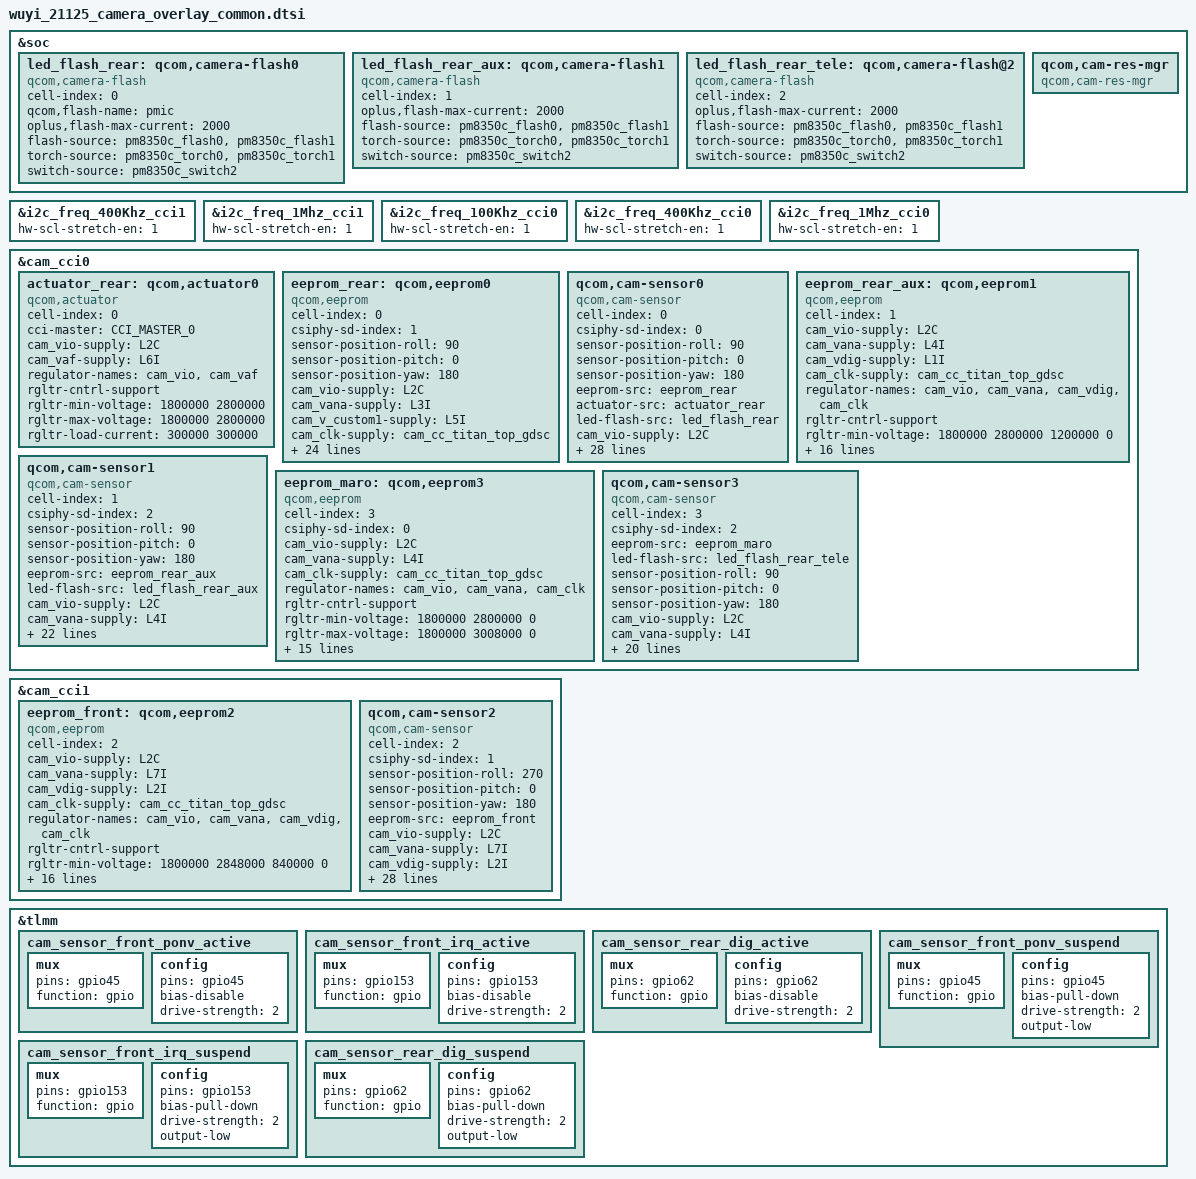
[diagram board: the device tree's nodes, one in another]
#include <dt-bindings/clock/qcom,camcc-diwali.h>
#include <dt-bindings/msm-camera.h>

&soc {
	led_flash_rear: qcom,camera-flash0 {
		cell-index = <0>;
		compatible = "qcom,camera-flash";
		qcom,flash-name = "pmic";
		oplus,flash-max-current = <2000>;
		flash-source = <&pm8350c_flash0  &pm8350c_flash1>;
		torch-source = <&pm8350c_torch0  &pm8350c_torch1>;
		switch-source = <&pm8350c_switch2>;
		status = "ok";
	};

	led_flash_rear_aux: qcom,camera-flash1 {
		cell-index = <1>;
		compatible = "qcom,camera-flash";
		oplus,flash-max-current = <2000>;
		flash-source = <&pm8350c_flash0  &pm8350c_flash1>;
		torch-source = <&pm8350c_torch0  &pm8350c_torch1>;
		switch-source = <&pm8350c_switch2>;
		status = "ok";
	};

	led_flash_rear_tele: qcom,camera-flash@2 {
		cell-index = <2>;
		compatible = "qcom,camera-flash";
		oplus,flash-max-current = <2000>;
		flash-source = <&pm8350c_flash0  &pm8350c_flash1>;
		torch-source = <&pm8350c_torch0  &pm8350c_torch1>;
		switch-source = <&pm8350c_switch2>;
		status = "ok";
	};

	qcom,cam-res-mgr {
		compatible = "qcom,cam-res-mgr";
		status = "ok";
	};
};

&i2c_freq_400Khz_cci1 {
    hw-scl-stretch-en = <1>;
};

&i2c_freq_1Mhz_cci1 {
    hw-scl-stretch-en = <1>;
};

&i2c_freq_100Khz_cci0 {
    hw-scl-stretch-en = <1>;
};

&i2c_freq_400Khz_cci0 {
    hw-scl-stretch-en = <1>;
};

&i2c_freq_1Mhz_cci0 {
    hw-scl-stretch-en = <1>;
};

&cam_cci0 {
	actuator_rear: qcom,actuator0 {
		cell-index = <0>;
		compatible = "qcom,actuator";
		cci-master = <CCI_MASTER_0>;
		cam_vio-supply = <&L2C>;
		cam_vaf-supply = <&L6I>;
		regulator-names = "cam_vio", "cam_vaf";
		rgltr-cntrl-support;
		rgltr-min-voltage = <1800000 2800000>;
		rgltr-max-voltage = <1800000 2800000>;
		rgltr-load-current = <300000 300000>;
	};

	eeprom_rear: qcom,eeprom0 {
		cell-index = <0>;
		compatible = "qcom,eeprom";
		csiphy-sd-index = <1>;
		sensor-position-roll = <90>;
		sensor-position-pitch = <0>;
		sensor-position-yaw = <180>;
		cam_vio-supply = <&L2C>;
		cam_vana-supply = <&L3I>;
		cam_v_custom1-supply = <&L5I>;
		cam_clk-supply = <&cam_cc_titan_top_gdsc>;
		regulator-names = "cam_vio", "cam_vana", "cam_v_custom1", "cam_clk";
		rgltr-cntrl-support;
		rgltr-min-voltage = <1800000 2800000 1824000 0>;
		rgltr-max-voltage = <1800000 2904000 2800000 0>;
		rgltr-load-current = <300000 300000 300000 0>;
		gpio-no-mux = <0>;
		pinctrl-names = "cam_default", "cam_suspend";
		pinctrl-0 = <&cam_sensor_mclk1_active
			&cam_sensor_active_rst1
			&cam_sensor_rear_dig_active>;
		pinctrl-1 = <&cam_sensor_mclk1_suspend
			&cam_sensor_suspend_rst1
			&cam_sensor_rear_dig_suspend>;
		gpios = <&tlmm 65 0>,
			<&tlmm 21 0>,
			<&tlmm 62 0>;
		gpio-reset = <1>;
		gpio-custom1 = <2>;
		gpio-req-tbl-num = <0 1 2>;
		gpio-req-tbl-flags = <1 0 0>;
		gpio-req-tbl-label = "CAMIF_MCLK1",
					"CAM_RESET1","CAM_VDIG1";
		cci-master = <CCI_MASTER_0>;
		status = "ok";
		clocks = <&camcc CAM_CC_MCLK1_CLK>;
		clock-names = "cam_clk";
		clock-cntl-level = "nominal";
		clock-rates = <19200000>;
	};

	qcom,cam-sensor0 {//main camera
		cell-index = <0>;
		compatible = "qcom,cam-sensor";
		csiphy-sd-index = <0>;
		sensor-position-roll = <90>;
		sensor-position-pitch = <0>;
		sensor-position-yaw = <180>;
		eeprom-src = <&eeprom_rear>;
		actuator-src = <&actuator_rear>;
		led-flash-src = <&led_flash_rear>;
		cam_vio-supply = <&L2C>;
		cam_vana-supply = <&L3I>;
		cam_v_custom1-supply = <&L5I>;
		cam_clk-supply = <&cam_cc_titan_top_gdsc>;
		regulator-names = "cam_vio", "cam_vana", "cam_v_custom1", "cam_clk";
		rgltr-cntrl-support;
		rgltr-min-voltage = <1800000 2800000 1824000 0>;
		rgltr-max-voltage = <1800000 2904000 2800000 0>;
		rgltr-load-current = <300000 300000 300000 0>;
		gpio-no-mux = <0>;
		pinctrl-names = "cam_default", "cam_suspend";
		pinctrl-0 = <&cam_sensor_mclk1_active
			&cam_sensor_active_rst1
			&cam_sensor_rear_dig_active>;
		pinctrl-1 = <&cam_sensor_mclk1_suspend
			&cam_sensor_suspend_rst1
			&cam_sensor_rear_dig_suspend>;
		gpios = <&tlmm 65 0>,
			<&tlmm 21 0>,
			<&tlmm 62 0>;
		gpio-reset = <1>;
		gpio-custom1 = <2>;
		gpio-req-tbl-num = <0 1 2>;
		gpio-req-tbl-flags = <1 0 0>;
		gpio-req-tbl-label = "CAMIF_MCLK1",
					"CAM_RESET1","CAM_VDIG1";
		cci-master = <CCI_MASTER_0>;
		status = "ok";
		clocks = <&camcc CAM_CC_MCLK1_CLK>;
		clock-names = "cam_clk";
		clock-cntl-level = "nominal";
		clock-rates = <19200000>;
		is-read-eeprom = <3>;
	};

	eeprom_rear_aux: qcom,eeprom1 {
		cell-index = <1>;
		compatible = "qcom,eeprom";
		cam_vio-supply = <&L2C>;
		cam_vana-supply = <&L4I>;
		cam_vdig-supply = <&L1I>;
		cam_clk-supply = <&cam_cc_titan_top_gdsc>;
		regulator-names = "cam_vio", "cam_vana",
			"cam_vdig", "cam_clk";
		rgltr-cntrl-support;
		rgltr-min-voltage = <1800000 2800000 1200000 0>;
		rgltr-max-voltage = <1800000 2904000 1200000 0>;
		rgltr-load-current = <300000 300000 1200000 0>;
		gpio-no-mux = <0>;
		pinctrl-names = "cam_default", "cam_suspend";
		pinctrl-0 = <&cam_sensor_mclk2_active
			&cam_sensor_active_rst2>;
		pinctrl-1 = <&cam_sensor_mclk2_suspend
			&cam_sensor_suspend_rst2>;
		gpios = <&tlmm 66 0>,
			<&tlmm 78 0>;
		gpio-reset = <1>;
		gpio-req-tbl-num = <0 1>;
		gpio-req-tbl-flags = <1 0>;
		gpio-req-tbl-label = "CAMIF_MCLK2",
					"CAM_RESET2";
		cci-master = <CCI_MASTER_1>;
		status = "ok";
		clocks = <&camcc CAM_CC_MCLK2_CLK>;
		clock-names = "cam_clk";
		clock-cntl-level = "nominal";
		clock-rates = <24000000>;
	};

	qcom,cam-sensor1 {//wide camera
		cell-index = <1>;
		compatible = "qcom,cam-sensor";
		csiphy-sd-index = <2>;
		sensor-position-roll = <90>;
		sensor-position-pitch = <0>;
		sensor-position-yaw = <180>;
		eeprom-src = <&eeprom_rear_aux>;
		led-flash-src = <&led_flash_rear_aux>;
		cam_vio-supply = <&L2C>;
		cam_vana-supply = <&L4I>;
		cam_vdig-supply = <&L1I>;
		cam_clk-supply = <&cam_cc_titan_top_gdsc>;
		regulator-names = "cam_vio", "cam_vana",
			"cam_vdig", "cam_clk";
		rgltr-cntrl-support;
		rgltr-min-voltage = <1800000 2800000 1200000 0>;
		rgltr-max-voltage = <1800000 2904000 1200000 0>;
		rgltr-load-current = <300000 300000 1200000 0>;
		gpio-no-mux = <0>;
		pinctrl-names = "cam_default", "cam_suspend";
		pinctrl-0 = <&cam_sensor_mclk2_active
			&cam_sensor_active_rst2>;
		pinctrl-1 = <&cam_sensor_mclk2_suspend
			&cam_sensor_suspend_rst2>;
		gpios = <&tlmm 66 0>,
			<&tlmm 78 0>;
		gpio-reset = <1>;
		gpio-req-tbl-num = <0 1>;
		gpio-req-tbl-flags = <1 0>;
		gpio-req-tbl-label = "CAMIF_MCLK2",
					"CAM_RESET2";
		cci-master = <CCI_MASTER_1>;
		status = "ok";
		clocks = <&camcc CAM_CC_MCLK2_CLK>;
		clock-names = "cam_clk";
		clock-cntl-level = "nominal";
		clock-rates = <24000000>;
	};

	eeprom_maro: qcom,eeprom3 {
		cell-index = <3>;
		compatible = "qcom,eeprom";
		csiphy-sd-index = <0>;
		cam_vio-supply = <&L2C>;
		cam_vana-supply = <&L4I>;
		cam_clk-supply = <&cam_cc_titan_top_gdsc>;
		regulator-names = "cam_vio", "cam_vana", "cam_clk";
		rgltr-cntrl-support;
		rgltr-min-voltage = <1800000 2800000 0>;
		rgltr-max-voltage = <1800000 3008000 0>;
		rgltr-load-current = <300000 300000 0>;
		gpio-no-mux = <0>;
		pinctrl-names = "cam_default", "cam_suspend";
		pinctrl-0 = <&cam_sensor_mclk4_active
			&cam_sensor_active_rst4>;
		pinctrl-1 = <&cam_sensor_mclk4_suspend
			&cam_sensor_suspend_rst4>;
		gpios = <&tlmm 68 0>,
			<&tlmm 80 0>;
		gpio-reset = <1>;
		gpio-req-tbl-num = <0 1>;
		gpio-req-tbl-flags = <1 0>;
		gpio-req-tbl-label = "CAMIF_MCLK4",
					"CAM_RESET4";
		cci-master = <CCI_MASTER_1>;
		clocks = <&camcc CAM_CC_MCLK4_CLK>;
		clock-names = "cam_clk";
		clock-cntl-level = "nominal";
		clock-rates = <24000000>;
		status = "ok";
	};

	qcom,cam-sensor3 {//maro camera
		cell-index = <3>;
		compatible = "qcom,cam-sensor";
		csiphy-sd-index = <2>;
		eeprom-src = <&eeprom_maro>;
		led-flash-src = <&led_flash_rear_tele>;
		sensor-position-roll = <90>;
		sensor-position-pitch = <0>;
		sensor-position-yaw = <180>;
		cam_vio-supply = <&L2C>;
		cam_vana-supply = <&L4I>;
		cam_clk-supply = <&cam_cc_titan_top_gdsc>;
		regulator-names = "cam_vio", "cam_vana", "cam_clk";
		rgltr-cntrl-support;
		rgltr-min-voltage = <1800000 2800000 0>;
		rgltr-max-voltage = <1800000 3008000 0>;
		rgltr-load-current = <300000 300000 0>;
		gpio-no-mux = <0>;
		pinctrl-names = "cam_default", "cam_suspend";
		pinctrl-0 = <&cam_sensor_mclk4_active
			&cam_sensor_active_rst4>;
		pinctrl-1 = <&cam_sensor_mclk4_suspend
			&cam_sensor_suspend_rst4>;
		gpios = <&tlmm 68 0>,
			<&tlmm 80 0>;
		gpio-reset = <1>;
		gpio-req-tbl-num = <0 1>;
		gpio-req-tbl-flags = <1 0>;
		gpio-req-tbl-label = "CAMIF_MCLK4",
					"CAM_RESET4";
		cci-master = <CCI_MASTER_1>;
		clocks = <&camcc CAM_CC_MCLK4_CLK>;
		clock-names = "cam_clk";
		clock-cntl-level = "nominal";
		clock-rates = <24000000>;
		status = "ok";
	};
};

&cam_cci1 {
	eeprom_front: qcom,eeprom2 {
		cell-index = <2>;
		compatible = "qcom,eeprom";
		cam_vio-supply = <&L2C>;
		cam_vana-supply = <&L7I>;
		cam_vdig-supply = <&L2I>;
		cam_clk-supply = <&cam_cc_titan_top_gdsc>;
		regulator-names = "cam_vio", "cam_vana",
			"cam_vdig", "cam_clk";
		rgltr-cntrl-support;
		rgltr-min-voltage = <1800000 2848000 840000 0>;
		rgltr-max-voltage = <1800000 3008000 1056000 0>;
		rgltr-load-current = <300000 300000 600000 0>;
		gpio-no-mux = <0>;
		pinctrl-names = "cam_default", "cam_suspend";
		pinctrl-0 = <&cam_sensor_mclk3_active
			&cam_sensor_active_rst3>;
		pinctrl-1 = <&cam_sensor_mclk3_suspend
			&cam_sensor_suspend_rst3>;
		gpios = <&tlmm 67 0>,
			<&tlmm 79 0>;
		gpio-reset = <1>;
		gpio-req-tbl-num = <0 1>;
		gpio-req-tbl-flags = <1 0>;
		gpio-req-tbl-label = "CAMIF_MCLK3",
					"CAM_RESET3";
		cci-master = <CCI_MASTER_0>;
		clocks = <&camcc CAM_CC_MCLK3_CLK>;
		clock-names = "cam_clk";
		clock-cntl-level = "turbo";
		clock-rates = <19200000>;
		status = "ok";
	};

	qcom,cam-sensor2 {//front camera
		cell-index = <2>;
		compatible = "qcom,cam-sensor", "zeku,aon-sensor";
		csiphy-sd-index = <1>;
		sensor-position-roll = <270>;
		sensor-position-pitch = <0>;
		sensor-position-yaw = <180>;
		eeprom-src = <&eeprom_front>;
		cam_vio-supply = <&L2C>;
		cam_vana-supply = <&L7I>;
		cam_vdig-supply = <&L2I>;
		cam_clk-supply = <&cam_cc_titan_top_gdsc>;
		regulator-names = "cam_vio", "cam_vana",
			"cam_vdig", "cam_clk";
		rgltr-cntrl-support;
		rgltr-min-voltage = <1800000 2848000 840000 0>;
		rgltr-max-voltage = <1800000 3008000 1056000 0>;
		rgltr-load-current = <300000 300000 600000 0>;
		gpio-no-mux = <0>;
		pinctrl-names = "cam_default", "cam_suspend";
		pinctrl-0 = <&cam_sensor_mclk3_active
			&cam_sensor_active_rst3
			&cam_sensor_front_ponv_active
			&cam_sensor_front_irq_active>;
		pinctrl-1 = <&cam_sensor_mclk3_suspend
			&cam_sensor_suspend_rst3
			&cam_sensor_front_ponv_suspend
			&cam_sensor_front_irq_suspend>;
		gpios = <&tlmm 67 0>,
			<&tlmm 79 0>,
			<&tlmm 45 0>,
			<&tlmm 153 0>;
		gpio-reset = <1>;
		gpio-custom1 = <2>;
		gpio-custom2 = <3>;
		gpio-req-tbl-num = <0 1 2 3>;
		gpio-req-tbl-flags = <1 0 0 0>;
		gpio-req-tbl-label = "CAMIF_MCLK3",
					"CAM_RESET3",
					"CAM_PONV_FRONT",
					"CAM_IRQ_FRONT";
		cci-master = <CCI_MASTER_0>;
		clocks = <&camcc CAM_CC_MCLK3_CLK>;
		clock-names = "cam_clk";
		clock-cntl-level = "turbo";
		clock-rates = <19200000>;
		status = "ok";
	};
};

&tlmm {
	cam_sensor_front_ponv_active: cam_sensor_front_ponv_active {
		/* RESET */
		mux {
			pins = "gpio45";
			function = "gpio";
		};

		config {
			pins = "gpio45";
			bias-disable; /* No PULL */
			drive-strength = <2>; /* 2 MA */
		};
	};

	cam_sensor_front_irq_active: cam_sensor_front_irq_active {
		/* RESET */
		mux {
			pins = "gpio153";
			function = "gpio";
		};

		config {
			pins = "gpio153";
			bias-disable; /* No PULL */
			drive-strength = <2>; /* 2 MA */
		};
	};

	cam_sensor_rear_dig_active: cam_sensor_rear_dig_active {
		/* RESET */
		mux {
			pins = "gpio62";
			function = "gpio";
		};

		config {
			pins = "gpio62";
			bias-disable; /* No PULL */
			drive-strength = <2>; /* 2 MA */
		};
	};

	cam_sensor_front_ponv_suspend: cam_sensor_front_ponv_suspend {
		/* RESET */
		mux {
			pins = "gpio45";
			function = "gpio";
		};

		config {
			pins = "gpio45";
			bias-pull-down; /* PULL DOWN */
			drive-strength = <2>; /* 2 MA */
			output-low;
		};
	};

	cam_sensor_front_irq_suspend: cam_sensor_front_irq_suspend {
		/* RESET */
		mux {
			pins = "gpio153";
			function = "gpio";
		};

		config {
			pins = "gpio153";
			bias-pull-down; /* PULL DOWN */
			drive-strength = <2>; /* 2 MA */
			output-low;
		};
	};

	cam_sensor_rear_dig_suspend: cam_sensor_rear_dig_suspend {
		/* RESET */
		mux {
			pins = "gpio62";
			function = "gpio";
		};

		config {
			pins = "gpio62";
			bias-pull-down; /* PULL DOWN */
			drive-strength = <2>; /* 2 MA */
			output-low;
		};
	};

};
